# Cortex-M3_RTSM register map
Vendor: ARM Ltd.
CPU: Cortex-M3_RTSM r0p0, little endian, MPU, VTOR, vendor SysTick, 8 interrupt priority bits
Registers are 32-bit, read-write, no defined reset value unless marked. A register's access mark holds for its fields unless they carry their own. Offsets are from the block's base; [hi:lo] are bit positions; {n}, {i} and the like mark numbered series; 'fields as' and 'values as' point back to an identical list.

## NVIC — Nested Vectored Interrupt Controller registers
Base ?
0x00 ICTR ro
  [2:0] INTLINESNUM — The total number of interrupt lines supported n, defined in groups of 32. That is, the total number of interrupt lines is up to (32*(INTLINESNUM+1)). However, the absolute maximum number of interrupts is 496, corresponding to the INTLINESNUM value 0b1111.
0x00 NVIC_ISER1
0x04 NVIC_ISER2
0x08 NVIC_ISER3
0x0C NVIC_ISER4
0xFC NVIC_ISER0
{0xFC+4i} NVIC_ISER{i} (i=5..7)
{0x17C+4i} NVIC_ICER{i} (i=0..7)
{0x1FC+4i} NVIC_ISPR{i} (i=0..7)
{0x27C+4i} NVIC_ICPR{i} (i=0..7)
{0x2FC+4i} NVIC_IABR{i} (i=0..7)
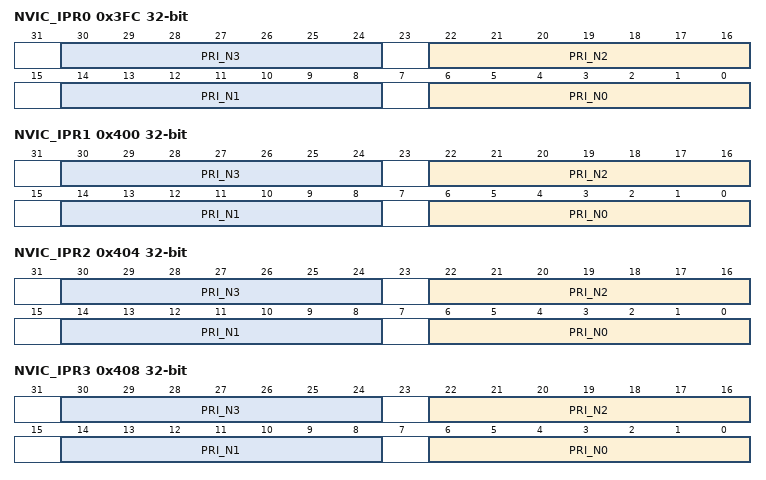
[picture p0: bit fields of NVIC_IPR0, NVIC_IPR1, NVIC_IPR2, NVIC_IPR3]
0x3FC NVIC_IPR0
  [8n+6:8n] PRI_N{n} (n=0..3) — Priority of interrupt {n}
0x400 NVIC_IPR1
  [8n+6:8n] PRI_N{n} (n=0..3) — Priority of interrupt {n+4}
0x404 NVIC_IPR2
  [8n+6:8n] PRI_N{n} (n=0..3) — Priority of interrupt {n+8}
0x408 NVIC_IPR3
  [8n+6:8n] PRI_N{n} (n=0..3) — Priority of interrupt {n+12}
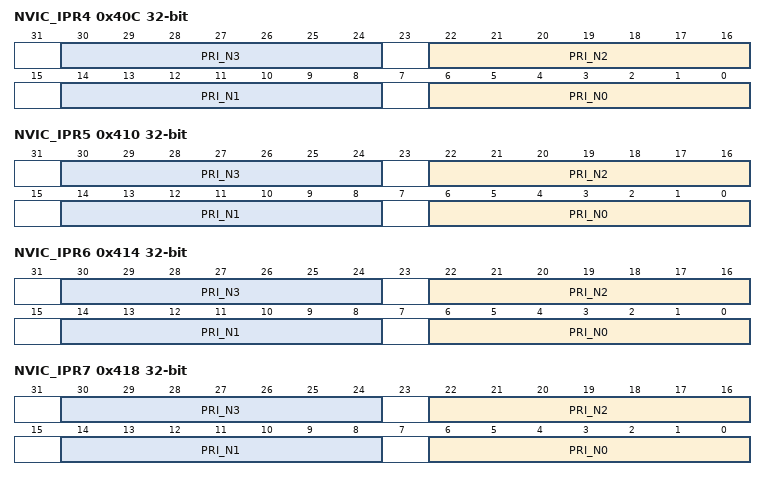
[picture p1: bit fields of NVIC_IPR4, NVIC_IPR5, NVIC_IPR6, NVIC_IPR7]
0x40C NVIC_IPR4
  [8n+6:8n] PRI_N{n} (n=0..3) — Priority of interrupt {n+16}
0x410 NVIC_IPR5
  [8n+6:8n] PRI_N{n} (n=0..3) — Priority of interrupt {n+20}
0x414 NVIC_IPR6
  [8n+6:8n] PRI_N{n} (n=0..3) — Priority of interrupt {n+24}
0x418 NVIC_IPR7
  [8n+6:8n] PRI_N{n} (n=0..3) — Priority of interrupt {n+28}
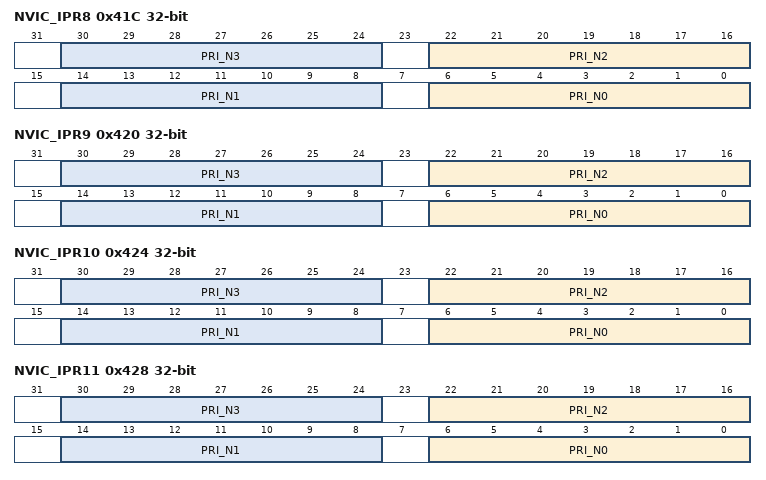
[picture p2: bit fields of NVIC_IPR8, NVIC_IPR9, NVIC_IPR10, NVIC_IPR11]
0x41C NVIC_IPR8
  [8n+6:8n] PRI_N{n} (n=0..3) — Priority of interrupt {n+32}
0x420 NVIC_IPR9
  [8n+6:8n] PRI_N{n} (n=0..3) — Priority of interrupt {n+36}
0x424 NVIC_IPR10
  [8n+6:8n] PRI_N{n} (n=0..3) — Priority of interrupt {n+40}
0x428 NVIC_IPR11
  [8n+6:8n] PRI_N{n} (n=0..3) — Priority of interrupt {n+44}
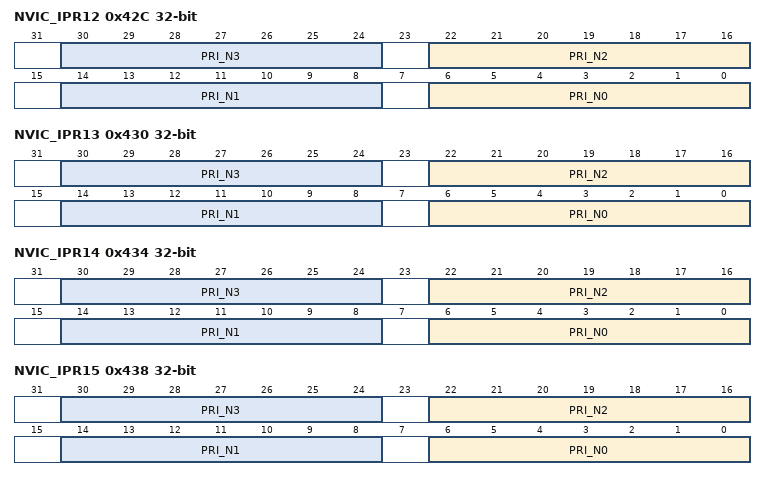
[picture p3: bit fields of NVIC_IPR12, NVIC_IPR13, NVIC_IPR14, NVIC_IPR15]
0x42C NVIC_IPR12
  [8n+6:8n] PRI_N{n} (n=0..3) — Priority of interrupt {n+48}
0x430 NVIC_IPR13
  [8n+6:8n] PRI_N{n} (n=0..3) — Priority of interrupt {n+52}
0x434 NVIC_IPR14
  [8n+6:8n] PRI_N{n} (n=0..3) — Priority of interrupt {n+56}
0x438 NVIC_IPR15
  [8n+6:8n] PRI_N{n} (n=0..3) — Priority of interrupt {n+60}
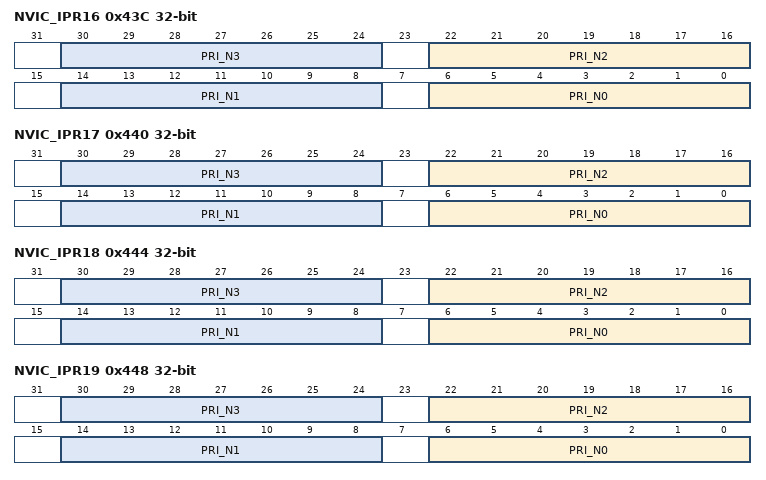
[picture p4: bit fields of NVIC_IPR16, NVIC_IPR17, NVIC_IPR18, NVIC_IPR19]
0x43C NVIC_IPR16
  [8n+6:8n] PRI_N{n} (n=0..3) — Priority of interrupt {n+64}
0x440 NVIC_IPR17
  [8n+6:8n] PRI_N{n} (n=0..3) — Priority of interrupt {n+68}
0x444 NVIC_IPR18
  [8n+6:8n] PRI_N{n} (n=0..3) — Priority of interrupt {n+72}
0x448 NVIC_IPR19
  [8n+6:8n] PRI_N{n} (n=0..3) — Priority of interrupt {n+76}
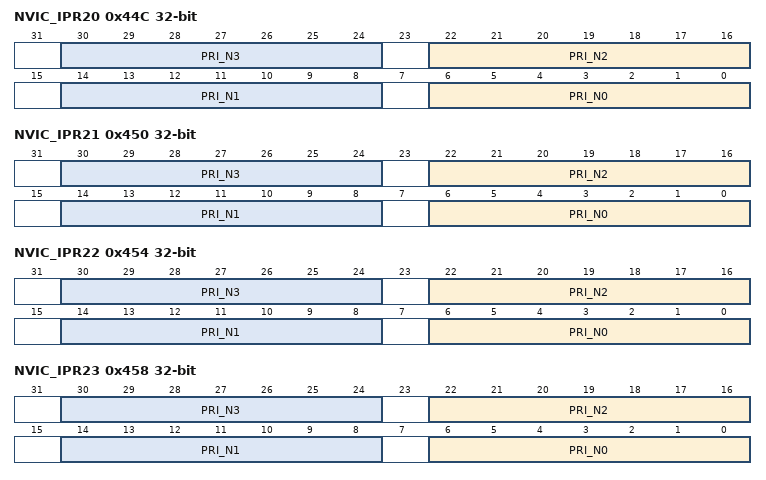
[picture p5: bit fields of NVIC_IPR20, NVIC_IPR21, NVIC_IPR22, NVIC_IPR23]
0x44C NVIC_IPR20
  [8n+6:8n] PRI_N{n} (n=0..3) — Priority of interrupt {n+80}
0x450 NVIC_IPR21
  [8n+6:8n] PRI_N{n} (n=0..3) — Priority of interrupt {n+84}
0x454 NVIC_IPR22
  [8n+6:8n] PRI_N{n} (n=0..3) — Priority of interrupt {n+88}
0x458 NVIC_IPR23
  [8n+6:8n] PRI_N{n} (n=0..3) — Priority of interrupt {n+92}
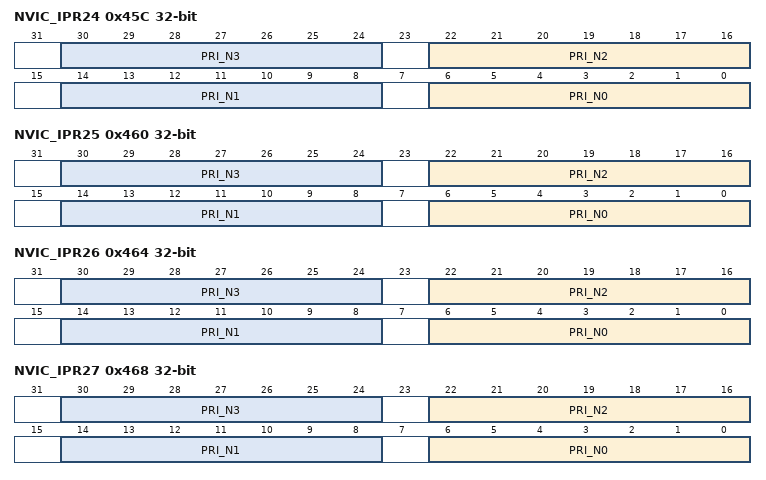
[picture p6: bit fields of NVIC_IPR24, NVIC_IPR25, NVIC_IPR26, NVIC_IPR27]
0x45C NVIC_IPR24
  [8n+6:8n] PRI_N{n} (n=0..3) — Priority of interrupt {n+96}
0x460 NVIC_IPR25
  [8n+6:8n] PRI_N{n} (n=0..3) — Priority of interrupt {n+100}
0x464 NVIC_IPR26
  [8n+6:8n] PRI_N{n} (n=0..3) — Priority of interrupt {n+104}
0x468 NVIC_IPR27
  [8n+6:8n] PRI_N{n} (n=0..3) — Priority of interrupt {n+108}
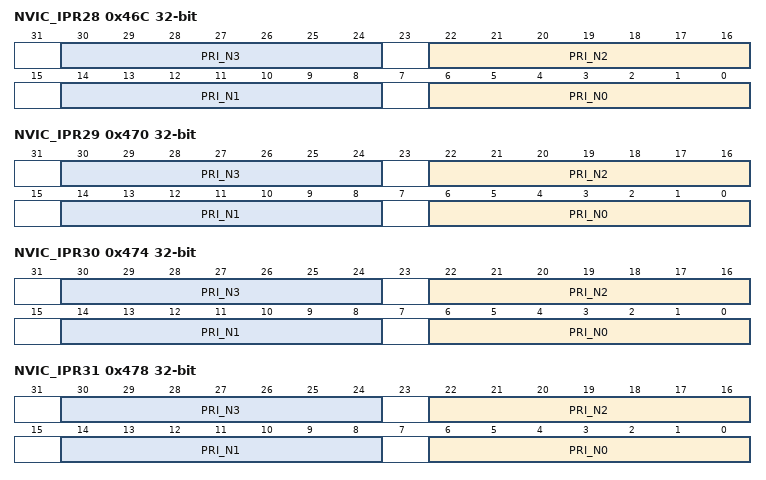
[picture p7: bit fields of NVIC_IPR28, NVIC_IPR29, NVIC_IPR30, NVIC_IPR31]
0x46C NVIC_IPR28
  [8n+6:8n] PRI_N{n} (n=0..3) — Priority of interrupt {n+112}
0x470 NVIC_IPR29
  [8n+6:8n] PRI_N{n} (n=0..3) — Priority of interrupt {n+116}
0x474 NVIC_IPR30
  [8n+6:8n] PRI_N{n} (n=0..3) — Priority of interrupt {n+120}
0x478 NVIC_IPR31
  [8n+6:8n] PRI_N{n} (n=0..3) — Priority of interrupt {n+124}
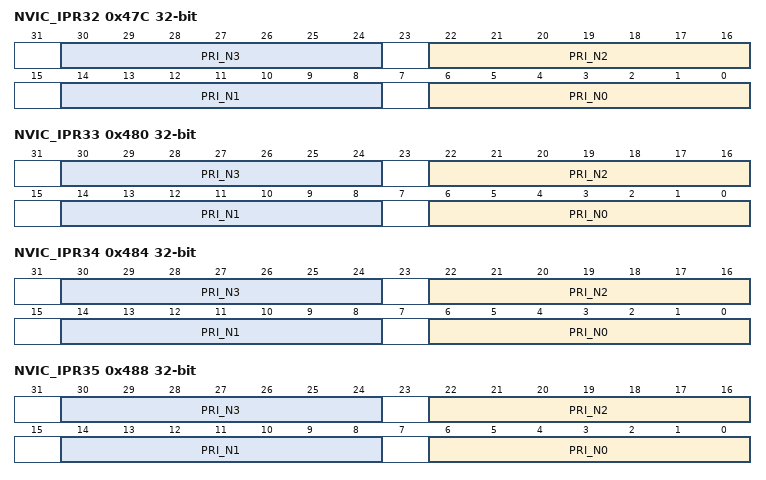
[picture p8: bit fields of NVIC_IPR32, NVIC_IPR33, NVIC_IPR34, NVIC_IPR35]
0x47C NVIC_IPR32
  [8n+6:8n] PRI_N{n} (n=0..3) — Priority of interrupt {n+128}
0x480 NVIC_IPR33
  [8n+6:8n] PRI_N{n} (n=0..3) — Priority of interrupt {n+132}
0x484 NVIC_IPR34
  [8n+6:8n] PRI_N{n} (n=0..3) — Priority of interrupt {n+136}
0x488 NVIC_IPR35
  [8n+6:8n] PRI_N{n} (n=0..3) — Priority of interrupt {n+140}
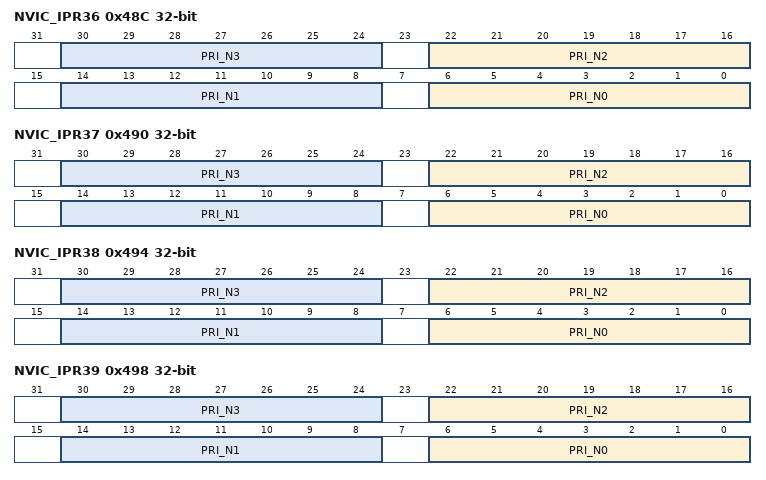
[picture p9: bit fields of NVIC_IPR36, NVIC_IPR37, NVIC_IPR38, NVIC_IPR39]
0x48C NVIC_IPR36
  [8n+6:8n] PRI_N{n} (n=0..3) — Priority of interrupt {n+144}
0x490 NVIC_IPR37
  [8n+6:8n] PRI_N{n} (n=0..3) — Priority of interrupt {n+148}
0x494 NVIC_IPR38
  [8n+6:8n] PRI_N{n} (n=0..3) — Priority of interrupt {n+152}
0x498 NVIC_IPR39
  [8n+6:8n] PRI_N{n} (n=0..3) — Priority of interrupt {n+156}
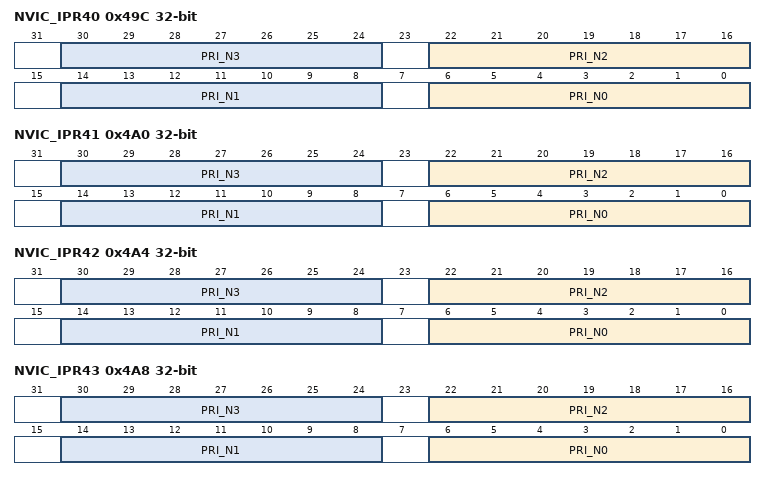
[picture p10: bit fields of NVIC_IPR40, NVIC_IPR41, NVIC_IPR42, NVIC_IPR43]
0x49C NVIC_IPR40
  [8n+6:8n] PRI_N{n} (n=0..3) — Priority of interrupt {n+160}
0x4A0 NVIC_IPR41
  [8n+6:8n] PRI_N{n} (n=0..3) — Priority of interrupt {n+164}
0x4A4 NVIC_IPR42
  [8n+6:8n] PRI_N{n} (n=0..3) — Priority of interrupt {n+168}
0x4A8 NVIC_IPR43
  [8n+6:8n] PRI_N{n} (n=0..3) — Priority of interrupt {n+172}
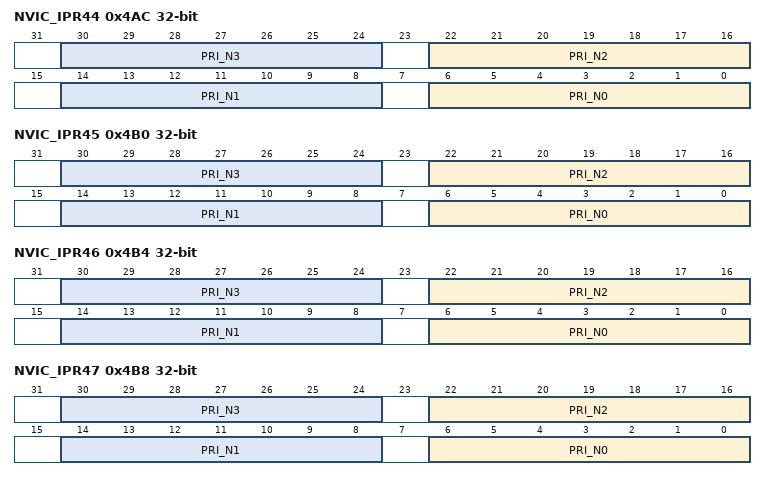
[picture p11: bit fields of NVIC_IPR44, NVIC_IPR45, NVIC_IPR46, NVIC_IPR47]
0x4AC NVIC_IPR44
  [8n+6:8n] PRI_N{n} (n=0..3) — Priority of interrupt {n+176}
0x4B0 NVIC_IPR45
  [8n+6:8n] PRI_N{n} (n=0..3) — Priority of interrupt {n+180}
0x4B4 NVIC_IPR46
  [8n+6:8n] PRI_N{n} (n=0..3) — Priority of interrupt {n+184}
0x4B8 NVIC_IPR47
  [8n+6:8n] PRI_N{n} (n=0..3) — Priority of interrupt {n+188}
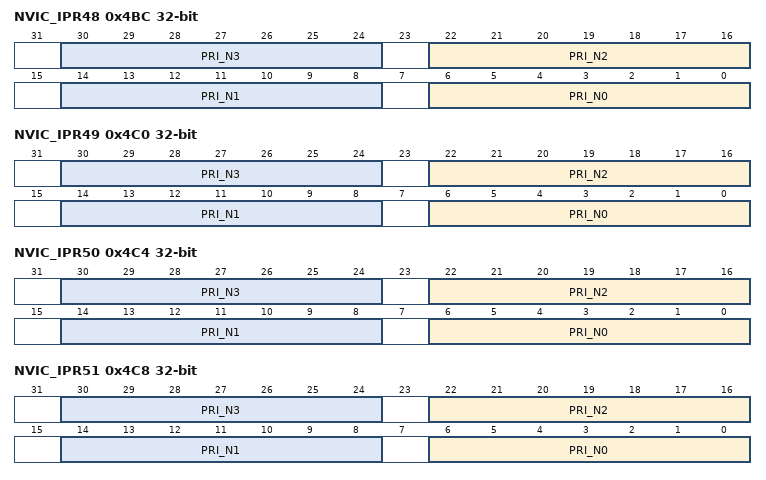
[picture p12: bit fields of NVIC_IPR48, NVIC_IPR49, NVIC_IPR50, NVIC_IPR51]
0x4BC NVIC_IPR48
  [8n+6:8n] PRI_N{n} (n=0..3) — Priority of interrupt {n+192}
0x4C0 NVIC_IPR49
  [8n+6:8n] PRI_N{n} (n=0..3) — Priority of interrupt {n+196}
0x4C4 NVIC_IPR50
  [8n+6:8n] PRI_N{n} (n=0..3) — Priority of interrupt {n+200}
0x4C8 NVIC_IPR51
  [8n+6:8n] PRI_N{n} (n=0..3) — Priority of interrupt {n+204}
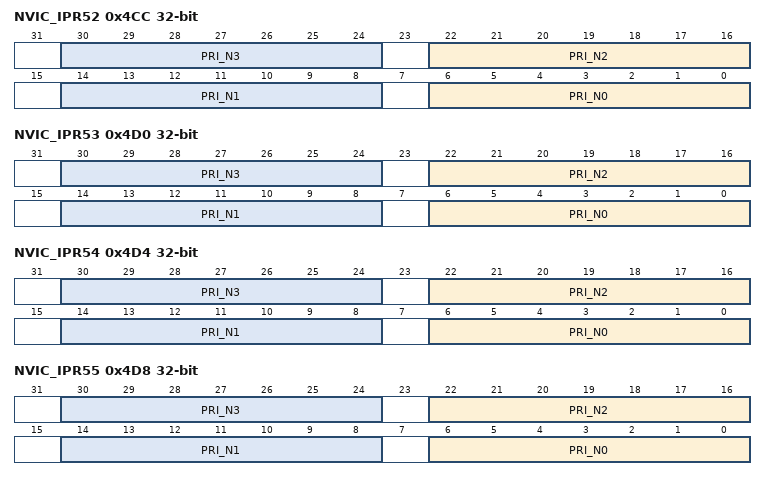
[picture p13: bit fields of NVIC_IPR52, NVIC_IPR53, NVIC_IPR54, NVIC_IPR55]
0x4CC NVIC_IPR52
  [8n+6:8n] PRI_N{n} (n=0..3) — Priority of interrupt {n+208}
0x4D0 NVIC_IPR53
  [8n+6:8n] PRI_N{n} (n=0..3) — Priority of interrupt {n+212}
0x4D4 NVIC_IPR54
  [8n+6:8n] PRI_N{n} (n=0..3) — Priority of interrupt {n+216}
0x4D8 NVIC_IPR55
  [8n+6:8n] PRI_N{n} (n=0..3) — Priority of interrupt {n+220}
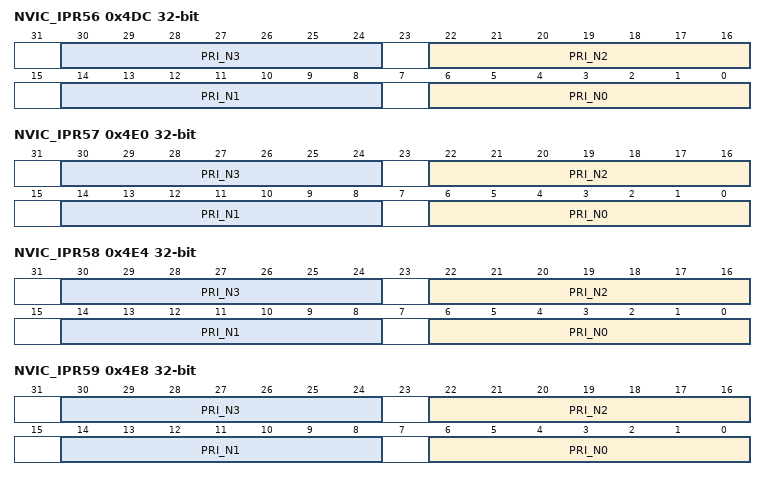
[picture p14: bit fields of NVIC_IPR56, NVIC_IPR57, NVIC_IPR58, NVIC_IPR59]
0x4DC NVIC_IPR56
  [8n+6:8n] PRI_N{n} (n=0..3) — Priority of interrupt {n+224}
0x4E0 NVIC_IPR57
  [8n+6:8n] PRI_N{n} (n=0..3) — Priority of interrupt {n+228}
0x4E4 NVIC_IPR58
  [8n+6:8n] PRI_N{n} (n=0..3) — Priority of interrupt {n+232}
0x4E8 NVIC_IPR59
  [8n+6:8n] PRI_N{n} (n=0..3) — Priority of interrupt {n+236}

## SysTick — System Timer registers
Base ?
0x00 STCSR
  [16] COUNTFLAG — Indicates whether the counter has counted to 0 since the last read of this register
  [2] CLKSOURCE — Indicates the SysTick clock source
  [1] TICKINT — Indicates whether counting to 0 causes the status of the SysTick exception to change to pending
  [0] ENABLE — Indicates the enabled status of the SysTick counter
0x04 STRVR
  [22:0] RELOAD — The value to load into the SYST_CVR register when the counter reaches 0
0x08 STCVR
  [22:0] CURRENT — This is the value of the counter at the time it is sampled
0x0C STCR ro
  [31] NOREF — Indicates whether the IMPLEMENTATION DEFINED reference clock is provided
  [30] SKEW — Indicates whether the 10ms calibration value is exact
  [22:0] TENMS — Optionally, holds a reload value to be used for 10ms (100Hz) timing, subject to system clock skew errors

## MPU — Memory Protection Unit
Base ?
0x00 MPU_TYPE ro
  [22:16] IREGION — Number of instruction regions supported by the MPU
  [14:8] DREGION — Number of regions supported by the MPU
  [0] SEPARATE — Indicates support for separate instruction and data address maps
0x00 MPU_RASR
  [28] XN — Execute Never
  [25:24] AP — Access permissions
  [20:19] TEX — MPU Region Attribute field
  [18] S — MPU Region Attribute field: Sharable
  [17] C — MPU Region Attribute field
  [16] B — MPU Region Attribute field
  [14:8] SRD — Subregion Disable
  [4:1] SIZE — Indicates the region size
  [0] ENABLE — Enables this region
0x04 MPU_CTRL
  [2] PRIVDEFENA — When the ENABLE bit is set to 1, Enables the default memory map as a background region for privileged access
  [1] HFNMIENA — When the ENABLE bit is set to 1, controls whether handlers executing with priority less than 0 access memory with the MPU enabled or with the MPU disabled
  [0] ENABLE — Enables the MPU
0x08 MPU_RNR
  [6:0] REGION — Indicates the memory region accessed by MPU_RBAR and MPU_RSAR
0x0C MPU_RBAR
  [30:5] ADDR — Base address of the region
  [4] VALID — On writes, indicates whether the region to update is specified by MPU_RNR.REGION, or by the REGION value specified in this write. When using the REGION value specified by this write, MPU_RNR.REGION is updated to this value
  [2:0] REGION — On writes, can specify the number of the region to update. On reads, returns bits [3:0] of MPU_RNR
{0xC+8i} MPU_RBAR_A{i} (i=1..3)
  fields as MPU_RBAR
{0x10+8i} MPU_RASR_A{i} (i=1..3)
  fields as MPU_RASR
